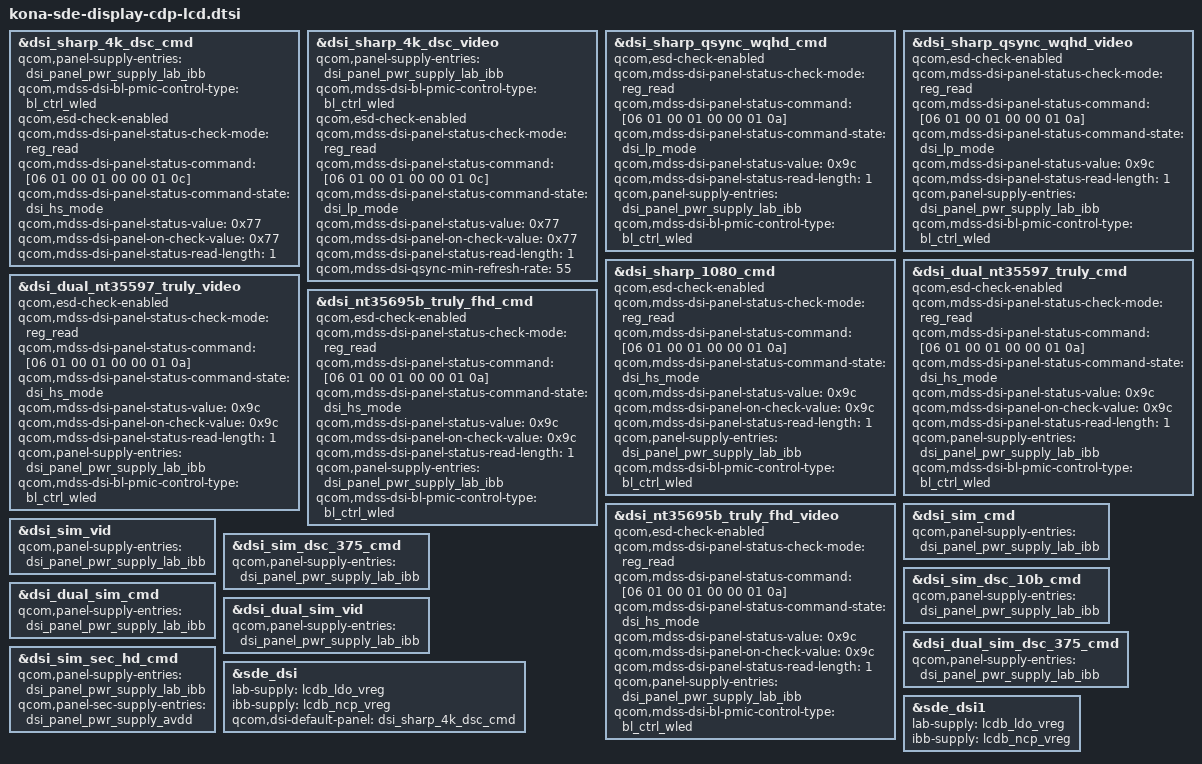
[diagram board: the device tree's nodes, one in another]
&dsi_sharp_4k_dsc_cmd {
	qcom,panel-supply-entries = <&dsi_panel_pwr_supply_lab_ibb>;
	qcom,mdss-dsi-bl-pmic-control-type = "bl_ctrl_wled";
	qcom,esd-check-enabled;
	qcom,mdss-dsi-panel-status-check-mode = "reg_read";
	qcom,mdss-dsi-panel-status-command = [06 01 00 01 00 00 01 0c];
	qcom,mdss-dsi-panel-status-command-state = "dsi_hs_mode";
	qcom,mdss-dsi-panel-status-value = <0x77>;
	qcom,mdss-dsi-panel-on-check-value = <0x77>;
	qcom,mdss-dsi-panel-status-read-length = <1>;
	/delete-property/ qcom,platform-en-gpio;
};

&dsi_sharp_4k_dsc_video {
	qcom,panel-supply-entries = <&dsi_panel_pwr_supply_lab_ibb>;
	qcom,mdss-dsi-bl-pmic-control-type = "bl_ctrl_wled";
	qcom,esd-check-enabled;
	qcom,mdss-dsi-panel-status-check-mode = "reg_read";
	qcom,mdss-dsi-panel-status-command = [06 01 00 01 00 00 01 0c];
	qcom,mdss-dsi-panel-status-command-state = "dsi_lp_mode";
	qcom,mdss-dsi-panel-status-value = <0x77>;
	qcom,mdss-dsi-panel-on-check-value = <0x77>;
	qcom,mdss-dsi-panel-status-read-length = <1>;
	qcom,mdss-dsi-qsync-min-refresh-rate = <55>;
	/delete-property/ qcom,platform-en-gpio;
};

&dsi_sharp_qsync_wqhd_cmd {
	qcom,esd-check-enabled;
	qcom,mdss-dsi-panel-status-check-mode = "reg_read";
	qcom,mdss-dsi-panel-status-command = [06 01 00 01 00 00 01 0a];
	qcom,mdss-dsi-panel-status-command-state = "dsi_lp_mode";
	qcom,mdss-dsi-panel-status-value = <0x9c>;
	qcom,mdss-dsi-panel-status-read-length = <1>;
	qcom,panel-supply-entries = <&dsi_panel_pwr_supply_lab_ibb>;
	qcom,mdss-dsi-bl-pmic-control-type = "bl_ctrl_wled";
	/delete-property/ qcom,platform-en-gpio;
};

&dsi_sharp_qsync_wqhd_video {
	qcom,esd-check-enabled;
	qcom,mdss-dsi-panel-status-check-mode = "reg_read";
	qcom,mdss-dsi-panel-status-command = [06 01 00 01 00 00 01 0a];
	qcom,mdss-dsi-panel-status-command-state = "dsi_lp_mode";
	qcom,mdss-dsi-panel-status-value = <0x9c>;
	qcom,mdss-dsi-panel-status-read-length = <1>;
	qcom,panel-supply-entries = <&dsi_panel_pwr_supply_lab_ibb>;
	qcom,mdss-dsi-bl-pmic-control-type = "bl_ctrl_wled";
	/delete-property/ qcom,platform-en-gpio;
};

&dsi_sharp_1080_cmd {
	qcom,esd-check-enabled;
	qcom,mdss-dsi-panel-status-check-mode = "reg_read";
	qcom,mdss-dsi-panel-status-command = [06 01 00 01 00 00 01 0a];
	qcom,mdss-dsi-panel-status-command-state = "dsi_hs_mode";
	qcom,mdss-dsi-panel-status-value = <0x9c>;
	qcom,mdss-dsi-panel-on-check-value = <0x9c>;
	qcom,mdss-dsi-panel-status-read-length = <1>;
	qcom,panel-supply-entries = <&dsi_panel_pwr_supply_lab_ibb>;
	qcom,mdss-dsi-bl-pmic-control-type = "bl_ctrl_wled";
};

&dsi_dual_nt35597_truly_cmd {
	qcom,esd-check-enabled;
	qcom,mdss-dsi-panel-status-check-mode = "reg_read";
	qcom,mdss-dsi-panel-status-command = [06 01 00 01 00 00 01 0a];
	qcom,mdss-dsi-panel-status-command-state = "dsi_hs_mode";
	qcom,mdss-dsi-panel-status-value = <0x9c>;
	qcom,mdss-dsi-panel-on-check-value = <0x9c>;
	qcom,mdss-dsi-panel-status-read-length = <1>;
	qcom,panel-supply-entries = <&dsi_panel_pwr_supply_lab_ibb>;
	qcom,mdss-dsi-bl-pmic-control-type = "bl_ctrl_wled";
};

&dsi_dual_nt35597_truly_video {
	qcom,esd-check-enabled;
	qcom,mdss-dsi-panel-status-check-mode = "reg_read";
	qcom,mdss-dsi-panel-status-command = [06 01 00 01 00 00 01 0a];
	qcom,mdss-dsi-panel-status-command-state = "dsi_hs_mode";
	qcom,mdss-dsi-panel-status-value = <0x9c>;
	qcom,mdss-dsi-panel-on-check-value = <0x9c>;
	qcom,mdss-dsi-panel-status-read-length = <1>;
	qcom,panel-supply-entries = <&dsi_panel_pwr_supply_lab_ibb>;
	qcom,mdss-dsi-bl-pmic-control-type = "bl_ctrl_wled";
};

&dsi_nt35695b_truly_fhd_cmd {
	qcom,esd-check-enabled;
	qcom,mdss-dsi-panel-status-check-mode = "reg_read";
	qcom,mdss-dsi-panel-status-command = [06 01 00 01 00 00 01 0a];
	qcom,mdss-dsi-panel-status-command-state = "dsi_hs_mode";
	qcom,mdss-dsi-panel-status-value = <0x9c>;
	qcom,mdss-dsi-panel-on-check-value = <0x9c>;
	qcom,mdss-dsi-panel-status-read-length = <1>;
	qcom,panel-supply-entries = <&dsi_panel_pwr_supply_lab_ibb>;
	qcom,mdss-dsi-bl-pmic-control-type = "bl_ctrl_wled";
};

&dsi_nt35695b_truly_fhd_video {
	qcom,esd-check-enabled;
	qcom,mdss-dsi-panel-status-check-mode = "reg_read";
	qcom,mdss-dsi-panel-status-command = [06 01 00 01 00 00 01 0a];
	qcom,mdss-dsi-panel-status-command-state = "dsi_hs_mode";
	qcom,mdss-dsi-panel-status-value = <0x9c>;
	qcom,mdss-dsi-panel-on-check-value = <0x9c>;
	qcom,mdss-dsi-panel-status-read-length = <1>;
	qcom,panel-supply-entries = <&dsi_panel_pwr_supply_lab_ibb>;
	qcom,mdss-dsi-bl-pmic-control-type = "bl_ctrl_wled";
};

&dsi_sim_cmd {
	qcom,panel-supply-entries = <&dsi_panel_pwr_supply_lab_ibb>;
};

&dsi_sim_vid {
	qcom,panel-supply-entries = <&dsi_panel_pwr_supply_lab_ibb>;
};

&dsi_sim_dsc_375_cmd {
	qcom,panel-supply-entries = <&dsi_panel_pwr_supply_lab_ibb>;
};

&dsi_sim_dsc_10b_cmd {
	qcom,panel-supply-entries = <&dsi_panel_pwr_supply_lab_ibb>;
};

&dsi_dual_sim_cmd {
	qcom,panel-supply-entries = <&dsi_panel_pwr_supply_lab_ibb>;
};

&dsi_dual_sim_vid {
	qcom,panel-supply-entries = <&dsi_panel_pwr_supply_lab_ibb>;
};

&dsi_dual_sim_dsc_375_cmd {
	qcom,panel-supply-entries = <&dsi_panel_pwr_supply_lab_ibb>;
};

&dsi_sim_sec_hd_cmd {
	qcom,panel-supply-entries = <&dsi_panel_pwr_supply_lab_ibb>;
	qcom,panel-sec-supply-entries = <&dsi_panel_pwr_supply_avdd>;
};

&sde_dsi {
	/delete-property/ avdd-supply;
	lab-supply = <&lcdb_ldo_vreg>;
	ibb-supply = <&lcdb_ncp_vreg>;
	qcom,dsi-default-panel = <&dsi_sharp_4k_dsc_cmd>;
};

&sde_dsi1 {
	lab-supply = <&lcdb_ldo_vreg>;
	ibb-supply = <&lcdb_ncp_vreg>;
};
